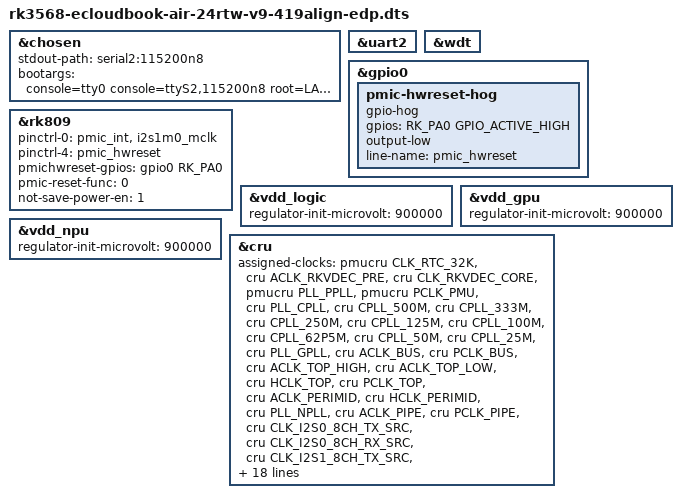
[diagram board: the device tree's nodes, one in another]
// SPDX-License-Identifier: (GPL-2.0+ OR MIT)
/*
 * P4-1 Display (eDP + VOP2 + PWM8 Backlight) DTS for China Mobile (ZTE)
 * CloudBook Air CT2000-24RTW:
 * Derives directly from v9-edp (enabling &vop, &vop_mmu, &pwm8 on top of
 * v5-g3-clean) with the proven 4.19 HW alignment from v8-419align-rootfs:
 *  - Move scmi_shmem out of reserved-memory + disable uart2 DMA
 *  - Remove pmic_hwreset (GPIO0_A0 pull-up) from rk809 pinctrl-0; add pinctrl-4,
 *    pmichwreset-gpios, pmic-reset-func = <0>, not-save-power-en = <1>, and gpio0 output-low hog
 *  - Align vdd_logic / vdd_gpu / vdd_npu regulator-init-microvolt = <900000>
 *  - Align &cru assigned-clocks / parents / rates to factory 4.19 DTB
 *  - Route kernel console to tty0 (eDP fbcon) and ttyS2 (115200n8 primary serial console)
 */

#include "rk3568-ecloudbook-air-24rtw-v9-edp.dts"
#include <dt-bindings/clock/rk3568-cru.h>
#include <dt-bindings/gpio/gpio.h>
#include <dt-bindings/pinctrl/rockchip.h>

/*
 * Linux 6.12 rk356x.dtsi already exposes the SCMI shared memory as
 * sram@10f000/sram@0 (label scmi_shmem) outside of reserved-memory, so the
 * older workaround that deleted shmem@10f000 and re-created it at the root
 * node only duplicated the label and broke the DTB build.
 */

&chosen {
	stdout-path = "serial2:115200n8";
	bootargs = "console=tty0 console=ttyS2,115200n8 root=LABEL=ROOTFS rootfstype=ext4 rootwait rw net.ifnames=0 clk_ignore_unused pd_ignore_unused cpuidle.off=1 systemd.show_status=1 systemd.default_timeout_start_sec=15s";
};

&uart2 {
	/delete-property/ dmas;
	/delete-property/ dma-names;
};

&wdt {
	status = "okay";
};

&gpio0 {
	pmic-hwreset-hog {
		gpio-hog;
		gpios = <RK_PA0 GPIO_ACTIVE_HIGH>;
		output-low;
		line-name = "pmic_hwreset";
	};
};

&rk809 {
	pinctrl-names = "default", "pmic-sleep", "pmic-power-off", "pmic-reset", "pmic-hwreset";
	pinctrl-0 = <&pmic_int>, <&i2s1m0_mclk>;
	pinctrl-4 = <&pmic_hwreset>;
	pmichwreset-gpios = <&gpio0 RK_PA0 GPIO_ACTIVE_HIGH>;
	pmic-reset-func = <0>;
	not-save-power-en = <1>;
};

&vdd_logic {
	regulator-init-microvolt = <900000>;
};

&vdd_gpu {
	regulator-init-microvolt = <900000>;
};

&vdd_npu {
	regulator-init-microvolt = <900000>;
};

&cru {
	assigned-clocks =
		<&pmucru CLK_RTC_32K>,
		<&cru ACLK_RKVDEC_PRE>,
		<&cru CLK_RKVDEC_CORE>,
		<&pmucru PLL_PPLL>,
		<&pmucru PCLK_PMU>,
		<&cru PLL_CPLL>,
		<&cru CPLL_500M>,
		<&cru CPLL_333M>,
		<&cru CPLL_250M>,
		<&cru CPLL_125M>,
		<&cru CPLL_100M>,
		<&cru CPLL_62P5M>,
		<&cru CPLL_50M>,
		<&cru CPLL_25M>,
		<&cru PLL_GPLL>,
		<&cru ACLK_BUS>,
		<&cru PCLK_BUS>,
		<&cru ACLK_TOP_HIGH>,
		<&cru ACLK_TOP_LOW>,
		<&cru HCLK_TOP>,
		<&cru PCLK_TOP>,
		<&cru ACLK_PERIMID>,
		<&cru HCLK_PERIMID>,
		<&cru PLL_NPLL>,
		<&cru ACLK_PIPE>,
		<&cru PCLK_PIPE>,
		<&cru CLK_I2S0_8CH_TX_SRC>,
		<&cru CLK_I2S0_8CH_RX_SRC>,
		<&cru CLK_I2S1_8CH_TX_SRC>,
		<&cru CLK_I2S1_8CH_RX_SRC>,
		<&cru CLK_I2S2_2CH_SRC>,
		<&cru CLK_I2S3_2CH_RX_SRC>,
		<&cru CLK_I2S3_2CH_TX_SRC>,
		<&cru MCLK_SPDIF_8CH_SRC>,
		<&cru ACLK_VOP>;
	assigned-clock-parents =
		<&pmucru CLK_RTC32K_FRAC>,
		<&cru PLL_GPLL>,
		<&cru PLL_GPLL>;
	assigned-clock-rates =
		<32768>,
		<300000000>,
		<300000000>,
		<200000000>,
		<100000000>,
		<1000000000>,
		<500000000>,
		<333000000>,
		<250000000>,
		<125000000>,
		<100000000>,
		<62500000>,
		<50000000>,
		<25000000>,
		<1188000000>,
		<150000000>,
		<100000000>,
		<500000000>,
		<400000000>,
		<150000000>,
		<100000000>,
		<300000000>,
		<150000000>,
		<1200000000>,
		<400000000>,
		<100000000>,
		<1188000000>,
		<1188000000>,
		<1188000000>,
		<1188000000>,
		<1188000000>,
		<1188000000>,
		<1188000000>,
		<1188000000>,
		<500000000>;
};
